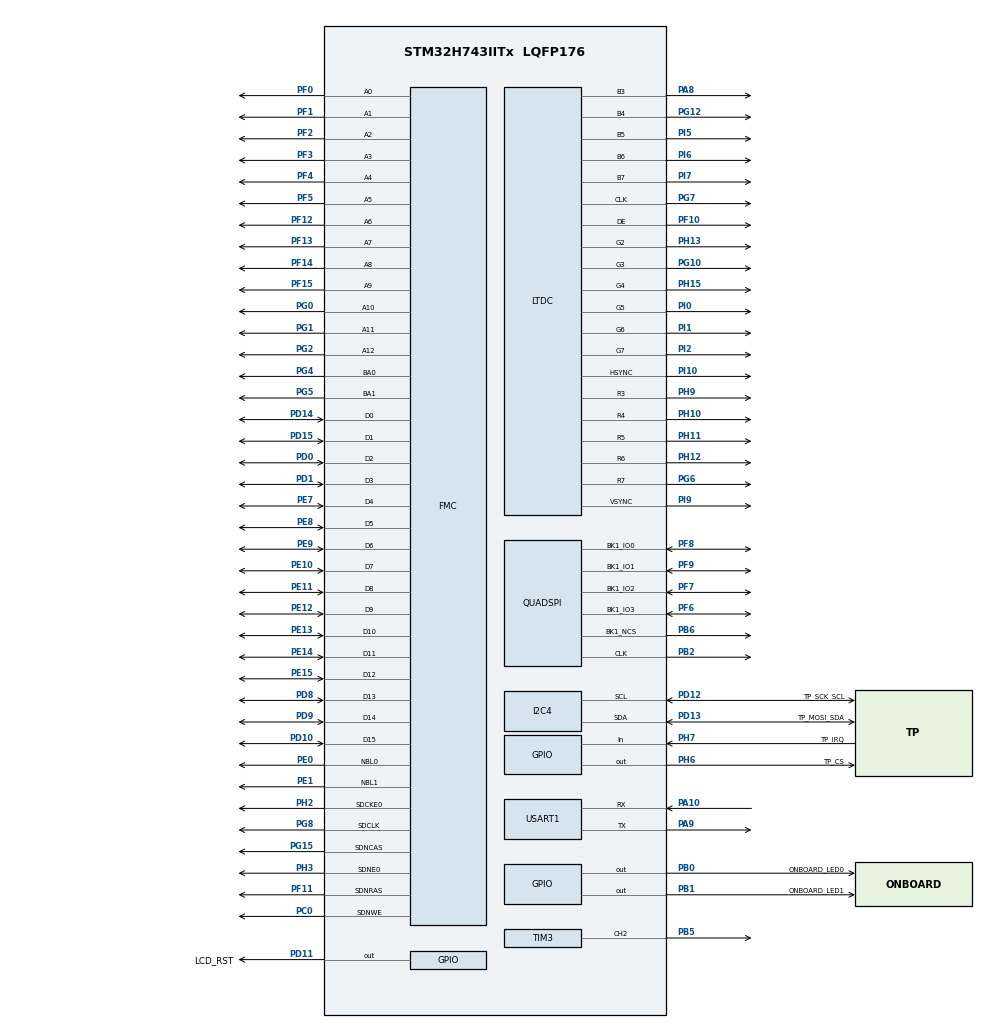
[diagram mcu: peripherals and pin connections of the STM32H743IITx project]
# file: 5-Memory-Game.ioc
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DMA2D.ColorMode=DMA2D_OUTPUT_RGB565
FMC.CASLatency1=FMC_SDRAM_CAS_LATENCY_3
FMC.ColumnBitsNumber1=FMC_SDRAM_COLUMN_BITS_NUM_9
FMC.ExitSelfRefreshDelay1=7
FMC.LoadToActiveDelay1=2
FMC.RCDDelay1=2
FMC.RPDelay1=2
FMC.ReadPipeDelay1=FMC_SDRAM_RPIPE_DELAY_1
FMC.RowCycleDelay1=7
FMC.SDClockPeriod1=FMC_SDRAM_CLOCK_PERIOD_2
FMC.SelfRefreshTime1=4
FMC.WriteRecoveryTime1=3
FREERTOS.Tasks01=defaultTask,24,128,StartDefaultTask,Default,NULL,Dynamic,NULL,NULL;TouchGfxTask,8,3072,TouchGfxTaskHandler,Default,NULL,Dynamic,NULL,NULL;LedTask,8,128,LedTaskHandler,Default,NULL,Dynamic,NULL,NULL
I2C4.Timing=0x307075B1
LTDC.ActiveH=600
LTDC.ActiveW=1024
LTDC.Alpha_L0=255
LTDC.Blue_L0=255
LTDC.FBStartAdress_L0=0xc0000000
LTDC.Green_L0=255
LTDC.HBP=157
LTDC.HFP=156
LTDC.HSync=8
LTDC.ImageHeight_L0=600
LTDC.ImageWidth_L0=1024
LTDC.Layers=0
LTDC.PixelFormat_L0=LTDC_PIXEL_FORMAT_RGB565
LTDC.Red_L0=255
LTDC.VBP=17
LTDC.VFP=16
LTDC.VSync=6
LTDC.WindowX1_L0=1024
LTDC.WindowY1_L0=600
Mcu.Family=STM32H7
Mcu.Name=STM32H743IITx
Mcu.Package=LQFP176
NVIC.DMA2D_IRQn=true\:5\:0\:true\:false\:true\:true\:true\:true\:true
NVIC.FMC_IRQn=true\:5\:0\:true\:false\:true\:true\:true\:true\:true
NVIC.LTDC_IRQn=true\:5\:0\:false\:false\:true\:true\:true\:true\:true
NVIC.PriorityGroup=NVIC_PRIORITYGROUP_4
NVIC.TIM7_IRQn=true\:0\:0\:true\:false\:true\:false\:false\:true\:true
NVIC.TimeBase=TIM7_IRQn
NVIC.TimeBaseIP=TIM7
PA10.Mode=Asynchronous
PA10.Signal=USART1_RX
PA8.Mode=RGB565
PA8.Signal=LTDC_B3
PA9.Mode=Asynchronous
PA9.Signal=USART1_TX
PB0.GPIO_Label=ONBOARD_LED0
PB0.Signal=GPIO_Output
PB1.GPIO_Label=ONBOARD_LED1
PB1.Signal=GPIO_Output
PB2.GPIO_Speed=GPIO_SPEED_FREQ_MEDIUM
PB2.Mode=Single Bank 1
PB2.Signal=QUADSPI_CLK
PB5.Signal=S_TIM3_CH2
PB6.GPIO_Speed=GPIO_SPEED_FREQ_MEDIUM
PB6.Mode=Single Bank 1
PB6.Signal=QUADSPI_BK1_NCS
PC0.Signal=FMC_SDNWE
PC14-OSC32_IN\ (OSC32_IN).Mode=LSE-External-Oscillator
PC14-OSC32_IN\ (OSC32_IN).Signal=RCC_OSC32_IN
PC15-OSC32_OUT\ (OSC32_OUT).Mode=LSE-External-Oscillator
PC15-OSC32_OUT\ (OSC32_OUT).Signal=RCC_OSC32_OUT
PD0.Signal=FMC_D2_DA2
PD1.Signal=FMC_D3_DA3
PD10.Signal=FMC_D15_DA15
PD11.GPIO_Label=LCD_RST
PD11.Signal=GPIO_Output
PD12.GPIO_Label=TP_SCK_SCL
PD12.Mode=I2C
PD12.Signal=I2C4_SCL
PD13.GPIO_Label=TP_MOSI_SDA
PD13.Mode=I2C
PD13.Signal=I2C4_SDA
PD14.Signal=FMC_D0_DA0
PD15.Signal=FMC_D1_DA1
PD8.Signal=FMC_D13_DA13
PD9.Signal=FMC_D14_DA14
PE0.Signal=FMC_NBL0
PE1.Signal=FMC_NBL1
PE10.Signal=FMC_D7_DA7
PE11.Signal=FMC_D8_DA8
PE12.Signal=FMC_D9_DA9
PE13.Signal=FMC_D10_DA10
PE14.Signal=FMC_D11_DA11
PE15.Signal=FMC_D12_DA12
PE7.Signal=FMC_D4_DA4
PE8.Signal=FMC_D5_DA5
PE9.Signal=FMC_D6_DA6
PF0.Signal=FMC_A0
PF1.Signal=FMC_A1
PF10.Mode=RGB565
PF10.Signal=LTDC_DE
PF11.Signal=FMC_SDNRAS
PF12.Signal=FMC_A6
PF13.Signal=FMC_A7
PF14.Signal=FMC_A8
PF15.Signal=FMC_A9
PF2.Signal=FMC_A2
PF3.Signal=FMC_A3
PF4.Signal=FMC_A4
PF5.Signal=FMC_A5
PF6.GPIO_Speed=GPIO_SPEED_FREQ_MEDIUM
PF6.Mode=Single Bank 1
PF6.Signal=QUADSPI_BK1_IO3
PF7.GPIO_Speed=GPIO_SPEED_FREQ_MEDIUM
PF7.Mode=Single Bank 1
PF7.Signal=QUADSPI_BK1_IO2
PF8.GPIO_Speed=GPIO_SPEED_FREQ_MEDIUM
PF8.Mode=Single Bank 1
PF8.Signal=QUADSPI_BK1_IO0
PF9.GPIO_Speed=GPIO_SPEED_FREQ_MEDIUM
PF9.Mode=Single Bank 1
PF9.Signal=QUADSPI_BK1_IO1
PG0.Signal=FMC_A10
PG1.Signal=FMC_A11
PG10.Mode=RGB565
PG10.Signal=LTDC_G3
PG12.Mode=RGB565
PG12.Signal=LTDC_B4
PG15.Signal=FMC_SDNCAS
PG2.Signal=FMC_A12
PG4.Signal=FMC_A14_BA0
PG5.Signal=FMC_A15_BA1
PG6.Mode=RGB565
PG6.Signal=LTDC_R7
PG7.Mode=RGB565
PG7.Signal=LTDC_CLK
PG8.Signal=FMC_SDCLK
PH0-OSC_IN\ (PH0).Mode=HSE-External-Oscillator
PH0-OSC_IN\ (PH0).Signal=RCC_OSC_IN
PH1-OSC_OUT\ (PH1).Mode=HSE-External-Oscillator
PH1-OSC_OUT\ (PH1).Signal=RCC_OSC_OUT
PH10.Mode=RGB565
PH10.Signal=LTDC_R4
PH11.Mode=RGB565
PH11.Signal=LTDC_R5
PH12.Mode=RGB565
PH12.Signal=LTDC_R6
PH13.Mode=RGB565
PH13.Signal=LTDC_G2
PH15.Mode=RGB565
PH15.Signal=LTDC_G4
PH2.Mode=SdramChipSelect1_1
PH2.Signal=FMC_SDCKE0
PH3.Mode=SdramChipSelect1_1
PH3.Signal=FMC_SDNE0
PH6.GPIO_Label=TP_CS
PH6.Signal=GPIO_Output
PH7.GPIO_Label=TP_IRQ
PH7.Signal=GPIO_Input
PH9.Mode=RGB565
PH9.Signal=LTDC_R3
PI0.Mode=RGB565
PI0.Signal=LTDC_G5
PI1.Mode=RGB565
PI1.Signal=LTDC_G6
PI10.Mode=RGB565
PI10.Signal=LTDC_HSYNC
PI2.Mode=RGB565
PI2.Signal=LTDC_G7
PI5.Mode=RGB565
PI5.Signal=LTDC_B5
PI6.Mode=RGB565
PI6.Signal=LTDC_B6
PI7.Mode=RGB565
PI7.Signal=LTDC_B7
PI9.Mode=RGB565
PI9.Signal=LTDC_VSYNC
ProjectManager.HeapSize=0x200
ProjectManager.StackSize=0x400
ProjectManager.TargetToolchain=STM32CubeIDE
QUADSPI.ClockPrescaler=1
QUADSPI.DeviceType=SPI_DEVICE_FLASH
QUADSPI.FlashSize=23
RCC.ADCFreq_Value=50390625
RCC.APB1Freq_Value=120000000
RCC.APB2Freq_Value=120000000
RCC.APB3Freq_Value=120000000
RCC.APB4Freq_Value=120000000
RCC.CortexFreq_Value=480000000
RCC.D1PPRE=RCC_APB3_DIV2
RCC.D2PPRE1=RCC_APB1_DIV2
RCC.D2PPRE2=RCC_APB2_DIV2
RCC.D3PPRE=RCC_APB4_DIV2
RCC.DIVM1=5
RCC.DIVM3=1
RCC.DIVN1=192
RCC.DIVN3=25
RCC.DIVQ3=20
RCC.DIVR3=22
RCC.HCLKFreq_Value=240000000
RCC.HPRE=RCC_HCLK_DIV2
RCC.PLL3FRACN=0
RCC.PLLFRACN=0
RCC.PLLSourceVirtual=RCC_PLLSOURCE_HSE
RCC.SYSCLKFreq_VALUE=480000000
RCC.SYSCLKSource=RCC_SYSCLKSOURCE_PLLCLK
RCC.USBFreq_Value=480000000
SH.FMC_A0.0=FMC_A0,13b-sda1
SH.FMC_A1.0=FMC_A1,13b-sda1
SH.FMC_A10.0=FMC_A10,13b-sda1
SH.FMC_A11.0=FMC_A11,13b-sda1
SH.FMC_A12.0=FMC_A12,13b-sda1
SH.FMC_A14_BA0.0=FMC_BA0,FourSdramBanks1
SH.FMC_A15_BA1.0=FMC_BA1,FourSdramBanks1
SH.FMC_A2.0=FMC_A2,13b-sda1
SH.FMC_A3.0=FMC_A3,13b-sda1
SH.FMC_A4.0=FMC_A4,13b-sda1
SH.FMC_A5.0=FMC_A5,13b-sda1
SH.FMC_A6.0=FMC_A6,13b-sda1
SH.FMC_A7.0=FMC_A7,13b-sda1
SH.FMC_A8.0=FMC_A8,13b-sda1
SH.FMC_A9.0=FMC_A9,13b-sda1
SH.FMC_D0_DA0.0=FMC_D0,sd-16b-d1
SH.FMC_D10_DA10.0=FMC_D10,sd-16b-d1
SH.FMC_D11_DA11.0=FMC_D11,sd-16b-d1
SH.FMC_D12_DA12.0=FMC_D12,sd-16b-d1
SH.FMC_D13_DA13.0=FMC_D13,sd-16b-d1
SH.FMC_D14_DA14.0=FMC_D14,sd-16b-d1
SH.FMC_D15_DA15.0=FMC_D15,sd-16b-d1
SH.FMC_D1_DA1.0=FMC_D1,sd-16b-d1
SH.FMC_D2_DA2.0=FMC_D2,sd-16b-d1
SH.FMC_D3_DA3.0=FMC_D3,sd-16b-d1
SH.FMC_D4_DA4.0=FMC_D4,sd-16b-d1
SH.FMC_D5_DA5.0=FMC_D5,sd-16b-d1
SH.FMC_D6_DA6.0=FMC_D6,sd-16b-d1
SH.FMC_D7_DA7.0=FMC_D7,sd-16b-d1
SH.FMC_D8_DA8.0=FMC_D8,sd-16b-d1
SH.FMC_D9_DA9.0=FMC_D9,sd-16b-d1
SH.FMC_NBL0.0=FMC_NBL0,Sd2ByteEnable1
SH.FMC_NBL1.0=FMC_NBL1,Sd2ByteEnable1
SH.FMC_SDCLK.0=FMC_SDCLK,13b-sda1
SH.FMC_SDNCAS.0=FMC_SDNCAS,13b-sda1
SH.FMC_SDNRAS.0=FMC_SDNRAS,13b-sda1
SH.FMC_SDNWE.0=FMC_SDNWE,13b-sda1
SH.S_TIM3_CH2.0=TIM3_CH2,PWM Generation2 CH2
STMicroelectronics.X-CUBE-TOUCHGFX.4.25.0.ApplicationCcGraphicsJjApplication=TouchGFXOoGenerator
STMicroelectronics.X-CUBE-TOUCHGFX.4.25.0.tgfx_address1=0xc012c000
STMicroelectronics.X-CUBE-TOUCHGFX.4.25.0.tgfx_address2=0xc0258000
STMicroelectronics.X-CUBE-TOUCHGFX.4.25.0.tgfx_buffering_strategy=Double
STMicroelectronics.X-CUBE-TOUCHGFX.4.25.0.tgfx_display_interface=disp_ltdc
STMicroelectronics.X-CUBE-TOUCHGFX.4.25.0.tgfx_framebuffer_stride=Enabled
STMicroelectronics.X-CUBE-TOUCHGFX.4.25.0.tgfx_hardware_accelerator=dma_2d
STMicroelectronics.X-CUBE-TOUCHGFX.4.25.0.tgfx_location=By Address
STMicroelectronics.X-CUBE-TOUCHGFX.4.25.0.tgfx_vector_fonts=Enabled
STMicroelectronics.X-CUBE-TOUCHGFX.4.25.0.tgfx_vector_rendering=Software
STMicroelectronics.X-CUBE-TOUCHGFX.4.25.0.tgfx_vsync=vsync_ltdc
STMicroelectronics.X-CUBE-TOUCHGFX.4.25.0_IsPackSelfContextualization=true
TIM3.Channel-PWM\ Generation2\ CH2=TIM_CHANNEL_2
TIM3.Period=1000 - 1
TIM3.Prescaler=1200 - 1
USART1.VirtualMode-Asynchronous=VM_ASYNC
VP_CRC_VS_CRC.Mode=CRC_Activate
VP_DMA2D_VS_DMA2D.Mode=DMA2D_Activate
VP_FREERTOS_VS_CMSIS_V2.Mode=CMSIS_V2
VP_MEMORYMAP_VS_MEMORYMAP.Mode=CurAppReg
VP_STMicroelectronics.X-CUBE-TOUCHGFX_VS_GraphicsJjApplication_4.25.0.Mode=GraphicsJjApplication
VP_SYS_VS_tim7.Mode=TIM7
board=custom

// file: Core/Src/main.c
/* USER CODE BEGIN Header */
/**
  ******************************************************************************
  * @file           : main.c
  * @brief          : Main program body
  ******************************************************************************
  * @attention
  *
  * Copyright (c) 2025 STMicroelectronics.
  * All rights reserved.
  *
  * This software is licensed under terms that can be found in the LICENSE file
  * in the root directory of this software component.
  * If no LICENSE file comes with this software, it is provided AS-IS.
  *
  ******************************************************************************
  */
/* USER CODE END Header */
#include "main.h"
#include "cmsis_os.h"
#include "crc.h"
#include "dma2d.h"
#include "i2c.h"
#include "ltdc.h"
#include "memorymap.h"
#include "quadspi.h"
#include "tim.h"
#include "usart.h"
#include "gpio.h"
#include "fmc.h"
#include "app_touchgfx.h"

/* USER CODE BEGIN Includes */
#include "Bsp_Gt9xx.h"
#include "Bsp_Lcd.h"
#include "Bsp_W25q64.h"
#include "w25q_mem.h"
/* USER CODE END Includes */

void SystemClock_Config(void);
void MX_FREERTOS_Init(void);

int main(void)
{

  /* MCU Configuration--------------------------------------------------------*/

  /* Reset of all peripherals, Initializes the Flash interface and the Systick. */
  HAL_Init();

  /* Configure the system clock */
  SystemClock_Config();

  /* Initialize all configured peripherals */
  MX_GPIO_Init();
  MX_USART1_UART_Init();
  MX_I2C4_Init();
  MX_FMC_Init();
  MX_LTDC_Init();
  MX_DMA2D_Init();
  MX_CRC_Init();
  MX_QUADSPI_Init();
  MX_TIM3_Init();
  MX_TouchGFX_Init();
  /* Call PreOsInit function */
  MX_TouchGFX_PreOSInit();
  /* USER CODE BEGIN 2 */
  W25Q_Init();
  QSPI_W25Qxx_MemoryMappedMode();
#ifndef LCD_BL_Pin
  HAL_TIM_PWM_Start(&TIMER_PWM_CHANNEL, PWM_PIN_CHANNEL);
#endif
  /* USER CODE END 2 */

  /* Init scheduler */
  osKernelInitialize();

  /* Call init function for freertos objects (in cmsis_os2.c) */
  MX_FREERTOS_Init();

  /* Start scheduler */
  osKernelStart();

  /* We should never get here as control is now taken by the scheduler */

  /* Infinite loop */
  while (1)
  {

  }
}

void SystemClock_Config(void)
{
  RCC_OscInitTypeDef RCC_OscInitStruct = {0};
  RCC_ClkInitTypeDef RCC_ClkInitStruct = {0};

  /** Supply configuration update enable
  */
  HAL_PWREx_ConfigSupply(PWR_LDO_SUPPLY);

  /** Configure the main internal regulator output voltage
  */
  __HAL_PWR_VOLTAGESCALING_CONFIG(PWR_REGULATOR_VOLTAGE_SCALE0);

  while(!__HAL_PWR_GET_FLAG(PWR_FLAG_VOSRDY)) {}

  /** Initializes the RCC Oscillators according to the specified parameters
  * in the RCC_OscInitTypeDef structure.
  */
  RCC_OscInitStruct.OscillatorType = RCC_OSCILLATORTYPE_HSE;
  RCC_OscInitStruct.HSEState = RCC_HSE_ON;
  RCC_OscInitStruct.PLL.PLLState = RCC_PLL_ON;
  RCC_OscInitStruct.PLL.PLLSource = RCC_PLLSOURCE_HSE;
  RCC_OscInitStruct.PLL.PLLM = 5;
  RCC_OscInitStruct.PLL.PLLN = 192;
  RCC_OscInitStruct.PLL.PLLP = 2;
  RCC_OscInitStruct.PLL.PLLQ = 2;
  RCC_OscInitStruct.PLL.PLLR = 2;
  RCC_OscInitStruct.PLL.PLLRGE = RCC_PLL1VCIRANGE_2;
  RCC_OscInitStruct.PLL.PLLVCOSEL = RCC_PLL1VCOWIDE;
  RCC_OscInitStruct.PLL.PLLFRACN = 0;
  if (HAL_RCC_OscConfig(&RCC_OscInitStruct) != HAL_OK)
  {
    Error_Handler();
  }

  /** Initializes the CPU, AHB and APB buses clocks
  */
  RCC_ClkInitStruct.ClockType = RCC_CLOCKTYPE_HCLK|RCC_CLOCKTYPE_SYSCLK
                              |RCC_CLOCKTYPE_PCLK1|RCC_CLOCKTYPE_PCLK2
                              |RCC_CLOCKTYPE_D3PCLK1|RCC_CLOCKTYPE_D1PCLK1;
  RCC_ClkInitStruct.SYSCLKSource = RCC_SYSCLKSOURCE_PLLCLK;
  RCC_ClkInitStruct.SYSCLKDivider = RCC_SYSCLK_DIV1;
  RCC_ClkInitStruct.AHBCLKDivider = RCC_HCLK_DIV2;
  RCC_ClkInitStruct.APB3CLKDivider = RCC_APB3_DIV2;
  RCC_ClkInitStruct.APB1CLKDivider = RCC_APB1_DIV2;
  RCC_ClkInitStruct.APB2CLKDivider = RCC_APB2_DIV2;
  RCC_ClkInitStruct.APB4CLKDivider = RCC_APB4_DIV2;

  if (HAL_RCC_ClockConfig(&RCC_ClkInitStruct, FLASH_LATENCY_4) != HAL_OK)
  {
    Error_Handler();
  }
}

void HAL_TIM_PeriodElapsedCallback(TIM_HandleTypeDef *htim)
{
  if (htim->Instance == TIM7) {
    HAL_IncTick();
  }
}

void Error_Handler(void)
{
  __disable_irq();
  while (1)
  {
  }
}
